# M051DE_v1 register map
File version: 1.0
Registers are 32-bit, read-write, reset 0x0 unless marked. A register's access mark holds for its fields unless they carry their own. Offsets are from the block's base; [hi:lo] are bit positions.

## EBI — EBI Register Map
Base 0x50010000
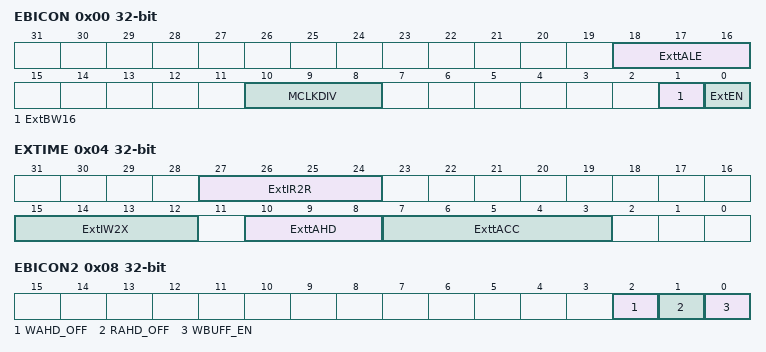
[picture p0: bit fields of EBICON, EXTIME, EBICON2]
0x00 EBICON — External Bus Interface General Control Register
  [18:16] ExttALE — Expand Time of ALE. This field is used to control the ALE pulse width (tALE) for address latch.
  [10:8] MCLKDIV — External Output Clock Divider. The frequency of EBI output clock (MCLK) is controlled by MCLKDIV as follows: Note: The default value of output clock is HCLK/1.
    0=MCLK frequency is HCLK/1; 1=MCLK frequency is HCLK/2; 2=MCLK frequency is HCLK/4; 3=MCLK frequency is HCLK/8; 4=MCLK frequency is HCLK/16; 5=MCLK frequency is HCLK/32
  [1] ExtBW16 — EBI Data Width 16-bit / 8-bit. This bit defines if the data bus is 8-bit or 16-bit.
    0=EBI data width is 8 bit; 1=EBI data width is 16 bit
  [0] ExtEN — EBI Enable Control. This bit is the functional enable bit for EBI.
    0=EBI function Disabled; 1=EBI function Enabled
0x04 EXTIME — External Bus Interface Timing Control Register
  [27:24] ExtIR2R — Idle State Cycle Between Read-read. When read action is finished and the next action is going to read, idle state is inserted and nCS signal return to high if ExtIR2R is not 0.
  [15:12] ExtIW2X — Idle State Cycle After Write. When write action is finished, idle state is inserted and nCS signal return to high if ExtIW2X is not 0.
  [10:8] ExttAHD — EBI Data Access Hold Time. ExttAHD defines data access hold time (tAHD).
  [7:3] ExttACC — EBI Data Access Time. ExttACC defines data access time (tACC).
0x08 EBICON2 — External Bus Interface General Control Register 2 (M05xxDN/DE Only)
  [2] WAHD_OFF — Access Hold Time Disable Control When Write
    0=tAHD is controlled by ExttAHD[2:0] when write through EBI; 1=Zero tAHD when write through EBI
  [1] RAHD_OFF — Access Hold Time Disable Control When Read
    0=tAHD is controlled by ExttAHD[2:0] when read through EBI; 1=Zero tAHD when read through EBI
  [0] WBUFF_EN — EBI Write Buffer Enable Control. Enable this function to improve CPU and EBI access performance.
    0=EBI write buffer Disabled; 1=EBI write buffer Enabled

## WDT — WDT Register Map
Base 0x40004000
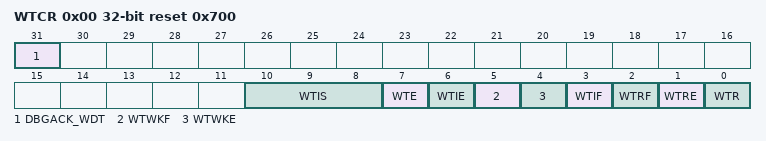
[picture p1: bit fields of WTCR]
0x00 WTCR reset 0x700 — Watchdog Timer Control Register
  [31] DBGACK_WDT — ICE Debug Mode Acknowledge Disable Control (Write Protect). WDT up counter will keep going no matter CPU is held by ICE or not.
    0=ICE debug mode acknowledgement effects WDT counting; 1=ICE debug mode acknowledgement Disabled
  [10:8] WTIS — Watchdog Timer Time-out Interval Selection (Write Protect). These three bits select the time-out interval period for the WDT.
    0=24 *TWDT; 1=26 *TWDT; 2=28 *TWDT; 3=210 *TWDT; 4=212 *TWDT; 5=214 *TWDT; 6=216 *TWDT; 7=218 *TWDT
  [7] WTE — Watchdog Timer Enable Control (Write Protect)
    0=WDT Disabled. (This action will reset the internal up counter value.); 1=WDT Enabled
  [6] WTIE — Watchdog Timer Time-out Interrupt Enable Control (Write Protect). If this bit is enabled, the WDT time-out interrupt signal is generated and inform to CPU.
    0=WDT time-out interrupt Disabled; 1=WDT time-out interrupt Enabled
  [5] WTWKF — Watchdog Timer Time-out Wake-up Flag. This bit indicates the interrupt wake-up flag status of WDT. Note: This bit is cleared by writing 1 to it.
    0=WDT does not cause chip wake-up; 1=Chip wake-up from Idle or Power-down mode if WDT time-out interrupt signal generated
  [4] WTWKE — Watchdog Timer Time-out Wake-up Function Control (Write Protect). If this bit is set to 1, while WTIF is generated to 1 and WTIE enabled, the WDT time-out interrupt signal will generate a wake-up trigger event to chip. Note: Chip can be woken-up by WDT time-out interrupt signal generated only if WDT clock source is selected to 10 kHz oscillator.
    0=Wake-up trigger event Disabled if WDT time-out interrupt signal generated; 1=Wake-up trigger event Enabled if WDT time-out interrupt signal generated
  [3] WTIF — Watchdog Timer Time-out Interrupt Flag. This bit will set to 1 while WDT up counter value reaches the selected WDT time-out interval. Note: This bit is cleared by writing 1 to it.
    0=WDT time-out interrupt did not occur; 1=WDT time-out interrupt occurred
  [2] WTRF — Watchdog Timer Time-out Reset Flag. This bit indicates the system has been reset by WDT time-out reset or not. Note: This bit is cleared by writing 1 to it.
    0=WDT time-out reset did not occur; 1=WDT time-out reset occurred
  [1] WTRE — Watchdog Timer Time-out Reset Enable Control (Write Protect). Setting this bit will enable the WDT time-out reset function If the WDT up counter value has not been cleared after the specific WDT reset delay period expires. Note: Fixed 1024 * TWDT delay period on M05xxBN. Selectable 3/18/130/1026 * TWDT delay period controlled by WTRDSEL on M05xxDE.
    0=WDT time-out reset function Disabled; 1=WDT time-out reset function Enabled
  [0] WTR — Reset Watchdog Timer Up Counter (Write Protect). Note: This bit will be automatically cleared by hardware.
    0=No effect; 1=Reset the internal 18-bit WDT up counter value
0x04 WTCRALT — Watchdog Timer Alternative Control Register (M05xxDN/DE Only)
  [1:0] WTRDSEL — Watchdog Timer Reset Delay Selection (Write Protect). When WDT time-out happened, software has a time named WDT Reset Delay Period to clear WDT counter to prevent WDT time-out reset happened. Software can select a suitable value of WDT Reset Delay Period for different WDT time-out period. Note: This register will be reset to 0 if WDT time-out reset happened.
    0=Watchdog Timer Reset Delay Period is 1026 * WDT_CLK; 1=Watchdog Timer Reset Delay Period is 130* WDT_CLK; 2=Watchdog Timer Reset Delay Period is 18 * WDT_CLK; 3=Watchdog Timer Reset Delay Period is 3 * WDT_CLK
